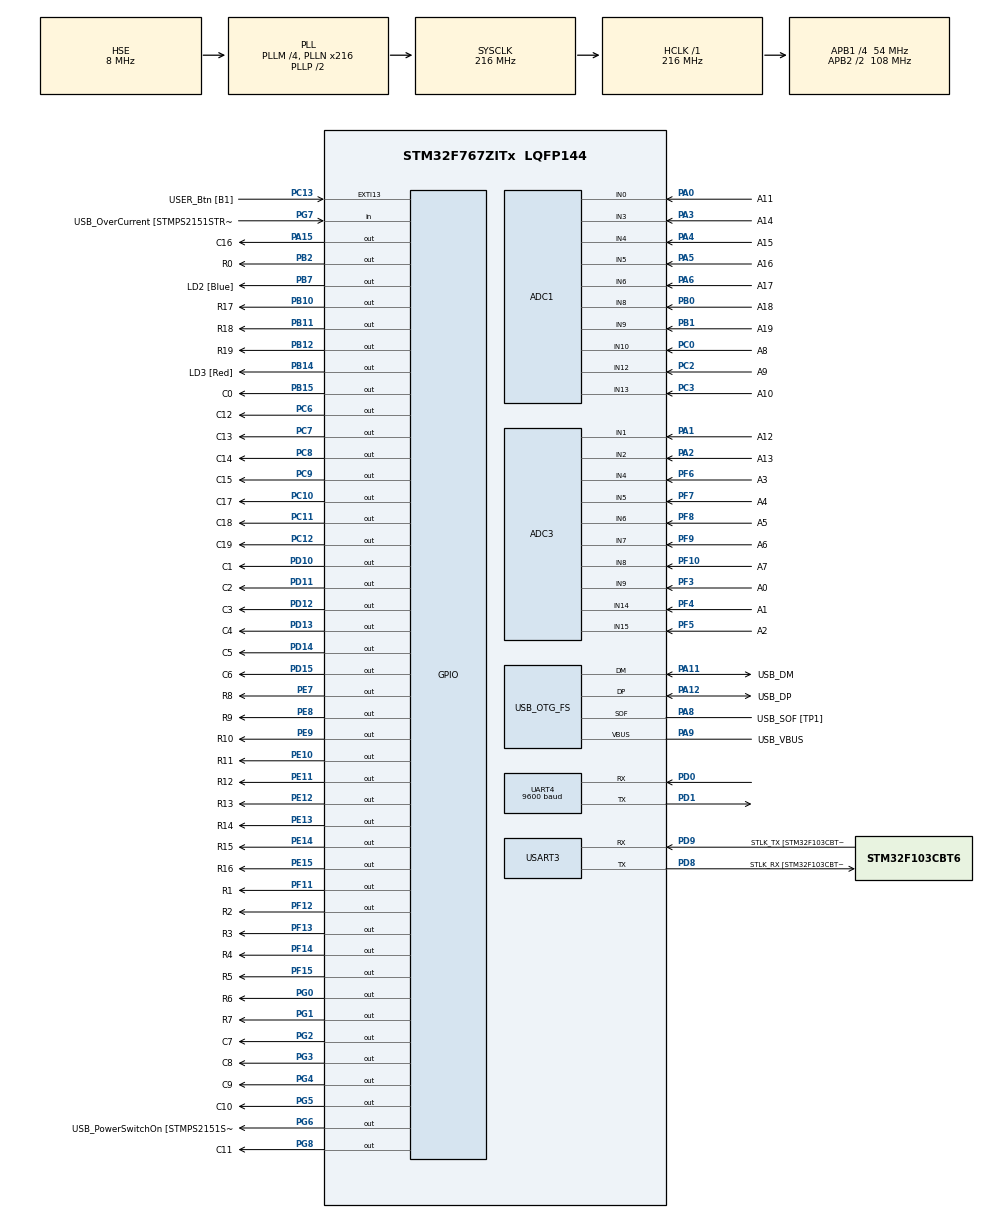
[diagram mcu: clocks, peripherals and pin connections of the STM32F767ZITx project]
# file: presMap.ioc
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ADC1.Channel-0\#ChannelRegularConversion=ADC_CHANNEL_0
ADC1.ContinuousConvMode=ENABLE
ADC1.EOCSelection=ADC_EOC_SEQ_CONV
ADC1.NbrOfConversion=1
ADC1.NbrOfConversionFlag=1
ADC1.Rank-0\#ChannelRegularConversion=1
ADC1.SamplingTime-0\#ChannelRegularConversion=ADC_SAMPLETIME_112CYCLES
ADC1.master=1
ADC3.Channel-3\#ChannelRegularConversion=ADC_CHANNEL_1
ADC3.ContinuousConvMode=ENABLE
ADC3.EOCSelection=ADC_EOC_SEQ_CONV
ADC3.NbrOfConversionFlag=1
ADC3.Rank-3\#ChannelRegularConversion=1
ADC3.SamplingTime-3\#ChannelRegularConversion=ADC_SAMPLETIME_112CYCLES
Dma.Request0=UART4_TX
Dma.UART4_TX.0.Direction=DMA_MEMORY_TO_PERIPH
Dma.UART4_TX.0.FIFOMode=DMA_FIFOMODE_DISABLE
Dma.UART4_TX.0.Instance=DMA1_Stream4
Dma.UART4_TX.0.MemDataAlignment=DMA_MDATAALIGN_BYTE
Dma.UART4_TX.0.MemInc=DMA_MINC_ENABLE
Dma.UART4_TX.0.Mode=DMA_CIRCULAR
Dma.UART4_TX.0.PeriphDataAlignment=DMA_PDATAALIGN_BYTE
Dma.UART4_TX.0.PeriphInc=DMA_PINC_DISABLE
Dma.UART4_TX.0.Priority=DMA_PRIORITY_MEDIUM
Mcu.Family=STM32F7
Mcu.Name=STM32F767ZITx
Mcu.Package=LQFP144
NVIC.DMA1_Stream4_IRQn=true\:0\:0\:false\:false\:true\:false
NVIC.OTG_FS_IRQn=true\:0\:0\:false\:false\:true\:false
NVIC.PriorityGroup=NVIC_PRIORITYGROUP_4
PA0/WKUP.GPIO_Label=A11
PA0/WKUP.Signal=ADCx_IN0
PA1.GPIO_Label=A12
PA1.Signal=ADCx_IN1
PA10.GPIO_Label=USB_ID
PA10.Signal=USB_OTG_FS_ID
PA11.GPIO_Label=USB_DM
PA11.Mode=Device_Only
PA11.Signal=USB_OTG_FS_DM
PA12.GPIO_Label=USB_DP
PA12.Mode=Device_Only
PA12.Signal=USB_OTG_FS_DP
PA13.GPIO_Label=TMS
PA13.Mode=Serial_Wire
PA13.Signal=SYS_JTMS-SWDIO
PA14.GPIO_Label=TCK
PA14.Mode=Serial_Wire
PA14.Signal=SYS_JTCK-SWCLK
PA15.GPIO_Label=C16
PA15.Signal=GPIO_Output
PA2.GPIO_Label=A13
PA2.Signal=ADCx_IN2
PA3.GPIO_Label=A14
PA3.Signal=ADCx_IN3
PA4.GPIO_Label=A15
PA4.Signal=ADCx_IN4
PA5.GPIO_Label=A16
PA5.Signal=ADCx_IN5
PA6.GPIO_Label=A17
PA6.Signal=ADCx_IN6
PA7.GPIO_Label=RMII_CRS_DV [LAN8742A-CZ-TR_CRS_DV]
PA7.Signal=ETH_CRS_DV
PA8.GPIO_Label=USB_SOF [TP1]
PA8.Mode=Activate_SOF_FS
PA8.Signal=USB_OTG_FS_SOF
PA9.GPIO_Label=USB_VBUS
PA9.Mode=Activate_VBUS
PA9.Signal=USB_OTG_FS_VBUS
PB0.GPIO_Label=A18
PB0.Signal=ADCx_IN8
PB1.GPIO_Label=A19
PB1.Signal=ADCx_IN9
PB10.GPIO_Label=R17
PB10.Signal=GPIO_Output
PB11.GPIO_Label=R18
PB11.Signal=GPIO_Output
PB12.GPIO_Label=R19
PB12.Signal=GPIO_Output
PB13.GPIO_Label=RMII_TXD1 [LAN8742A-CZ-TR_TXD1]
PB13.Signal=ETH_TXD1
PB14.GPIO_Label=LD3 [Red]
PB14.Signal=GPIO_Output
PB15.GPIO_Label=C0
PB15.Signal=GPIO_Output
PB2.GPIO_Label=R0
PB2.Signal=GPIO_Output
PB3.GPIO_Label=SWO
PB3.Signal=SYS_JTDO-SWO
PB7.GPIO_Label=LD2 [Blue]
PB7.Signal=GPIO_Output
PC0.GPIO_Label=A8
PC0.Signal=ADCx_IN10
PC1.GPIO_Label=RMII_MDC [LAN8742A-CZ-TR_MDC]
PC1.Signal=ETH_MDC
PC10.GPIO_Label=C17
PC10.Signal=GPIO_Output
PC11.GPIO_Label=C18
PC11.Signal=GPIO_Output
PC12.GPIO_Label=C19
PC12.Signal=GPIO_Output
PC13.GPIO_Label=USER_Btn [B1]
PC13.Signal=GPXTI13
PC14/OSC32_IN.Mode=LSE-External-Oscillator
PC14/OSC32_IN.Signal=RCC_OSC32_IN
PC15/OSC32_OUT.Mode=LSE-External-Oscillator
PC15/OSC32_OUT.Signal=RCC_OSC32_OUT
PC2.GPIO_Label=A9
PC2.Signal=ADCx_IN12
PC3.GPIO_Label=A10
PC3.Signal=ADCx_IN13
PC4.GPIO_Label=RMII_RXD0 [LAN8742A-CZ-TR_RXD0]
PC4.Signal=ETH_RXD0
PC5.GPIO_Label=RMII_RXD1 [LAN8742A-CZ-TR_RXD1]
PC5.Signal=ETH_RXD1
PC6.GPIO_Label=C12
PC6.Signal=GPIO_Output
PC7.GPIO_Label=C13
PC7.Signal=GPIO_Output
PC8.GPIO_Label=C14
PC8.Signal=GPIO_Output
PC9.GPIO_Label=C15
PC9.Signal=GPIO_Output
PD0.Mode=Asynchronous
PD0.Signal=UART4_RX
PD1.Mode=Asynchronous
PD1.Signal=UART4_TX
PD10.GPIO_Label=C1
PD10.Signal=GPIO_Output
PD11.GPIO_Label=C2
PD11.Signal=GPIO_Output
PD12.GPIO_Label=C3
PD12.Signal=GPIO_Output
PD13.GPIO_Label=C4
PD13.Signal=GPIO_Output
PD14.GPIO_Label=C5
PD14.Signal=GPIO_Output
PD15.GPIO_Label=C6
PD15.Signal=GPIO_Output
PD8.GPIO_Label=STLK_RX [STM32F103CBT6_PA3]
PD8.Mode=Asynchronous
PD8.Signal=USART3_TX
PD9.GPIO_Label=STLK_TX [STM32F103CBT6_PA2]
PD9.Mode=Asynchronous
PD9.Signal=USART3_RX
PE10.GPIO_Label=R11
PE10.Signal=GPIO_Output
PE11.GPIO_Label=R12
PE11.Signal=GPIO_Output
PE12.GPIO_Label=R13
PE12.Signal=GPIO_Output
PE13.GPIO_Label=R14
PE13.Signal=GPIO_Output
PE14.GPIO_Label=R15
PE14.Signal=GPIO_Output
PE15.GPIO_Label=R16
PE15.Signal=GPIO_Output
PE7.GPIO_Label=R8
PE7.Signal=GPIO_Output
PE8.GPIO_Label=R9
PE8.Signal=GPIO_Output
PE9.GPIO_Label=R10
PE9.Signal=GPIO_Output
PF10.GPIO_Label=A7
PF10.Mode=IN8
PF10.Signal=ADC3_IN8
PF11.GPIO_Label=R1
PF11.Signal=GPIO_Output
PF12.GPIO_Label=R2
PF12.Signal=GPIO_Output
PF13.GPIO_Label=R3
PF13.Signal=GPIO_Output
PF14.GPIO_Label=R4
PF14.Signal=GPIO_Output
PF15.GPIO_Label=R5
PF15.Signal=GPIO_Output
PF3.GPIO_Label=A0
PF3.Mode=IN9
PF3.Signal=ADC3_IN9
PF4.GPIO_Label=A1
PF4.Mode=IN14
PF4.Signal=ADC3_IN14
PF5.GPIO_Label=A2
PF5.Mode=IN15
PF5.Signal=ADC3_IN15
PF6.GPIO_Label=A3
PF6.Mode=IN4
PF6.Signal=ADC3_IN4
PF7.GPIO_Label=A4
PF7.Mode=IN5
PF7.Signal=ADC3_IN5
PF8.GPIO_Label=A5
PF8.Mode=IN6
PF8.Signal=ADC3_IN6
PF9.GPIO_Label=A6
PF9.Mode=IN7
PF9.Signal=ADC3_IN7
PG0.GPIO_Label=R6
PG0.Signal=GPIO_Output
PG1.GPIO_Label=R7
PG1.Signal=GPIO_Output
PG11.GPIO_Label=RMII_TX_EN [LAN8742A-CZ-TR_TXEN]
PG11.Signal=ETH_TX_EN
PG13.GPIO_Label=RMII_TXD0 [LAN8742A-CZ-TR_TXD0]
PG13.Signal=ETH_TXD0
PG2.GPIO_Label=C7
PG2.Signal=GPIO_Output
PG3.GPIO_Label=C8
PG3.Signal=GPIO_Output
PG4.GPIO_Label=C9
PG4.Signal=GPIO_Output
PG5.GPIO_Label=C10
PG5.Signal=GPIO_Output
PG6.GPIO_Label=USB_PowerSwitchOn [STMPS2151STR_EN]
PG6.Signal=GPIO_Output
PG7.GPIO_Label=USB_OverCurrent [STMPS2151STR_FAULT]
PG7.Signal=GPIO_Input
PG8.GPIO_Label=C11
PG8.Signal=GPIO_Output
PH0/OSC_IN.GPIO_Label=MCO [STM32F103CBT6_PA8]
PH0/OSC_IN.Mode=HSE-External-Clock-Source
PH0/OSC_IN.Signal=RCC_OSC_IN
PH1/OSC_OUT.Mode=HSE-External-Clock-Source
PH1/OSC_OUT.Signal=RCC_OSC_OUT
ProjectManager.HeapSize=0x200
ProjectManager.StackSize=0x400
ProjectManager.TargetToolchain=Makefile
RCC.48MHZClocksFreq_Value=24000000
RCC.AHBFreq_Value=216000000
RCC.APB1CLKDivider=RCC_HCLK_DIV4
RCC.APB1Freq_Value=54000000
RCC.APB1TimFreq_Value=108000000
RCC.APB2CLKDivider=RCC_HCLK_DIV2
RCC.APB2Freq_Value=108000000
RCC.APB2TimFreq_Value=216000000
RCC.CortexFreq_Value=216000000
RCC.HCLKFreq_Value=216000000
RCC.HSE_VALUE=8000000
RCC.HSI_VALUE=16000000
RCC.PLLM=4
RCC.PLLMUL=RCC_PLL_MUL9
RCC.PLLN=216
RCC.PLLQ=9
RCC.PRESCALERUSB=RCC_USBCLKSOURCE_PLL_DIV1_5
RCC.SYSCLKFreq_VALUE=216000000
RCC.SYSCLKSource=RCC_SYSCLKSOURCE_PLLCLK
RCC.SYSCLKSourceVirtual=RCC_SYSCLKSOURCE_PLLCLK
RCC.USBFreq_Value=48000000
RCC.VCOOutputFreq_Value=432000000
SH.ADCx_IN0.0=ADC1_IN0,IN0
SH.ADCx_IN1.0=ADC3_IN1,IN1
SH.ADCx_IN10.0=ADC1_IN10,IN10
SH.ADCx_IN12.0=ADC1_IN12,IN12
SH.ADCx_IN13.0=ADC1_IN13,IN13
SH.ADCx_IN2.0=ADC3_IN2,IN2
SH.ADCx_IN3.0=ADC1_IN3,IN3
SH.ADCx_IN4.0=ADC1_IN4,IN4
SH.ADCx_IN5.0=ADC1_IN5,IN5
SH.ADCx_IN6.0=ADC1_IN6,IN6
SH.ADCx_IN8.0=ADC1_IN8,IN8
SH.ADCx_IN9.0=ADC1_IN9,IN9
UART4.BaudRate=9600
USART3.VirtualMode-Asynchronous=VM_ASYNC
USB_DEVICE.CLASS_NAME_FS=CDC
USB_DEVICE.VirtualMode-CDC_FS=Cdc
USB_DEVICE.VirtualModeFS=Cdc_FS
USB_OTG_FS.VirtualMode=Device_Only
VP_USB_DEVICE_VS_USB_DEVICE_CDC_FS.Mode=CDC_FS
board=NUCLEO-F767ZI

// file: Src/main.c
/* USER CODE BEGIN Header */
/**
  ******************************************************************************
  * @file           : main.c
  * @brief          : Main program body
  ******************************************************************************
  ** This notice applies to any and all portions of this file
  * that are not between comment pairs USER CODE BEGIN and
  * USER CODE END. Other portions of this file, whether
  * inserted by the user or by software development tools
  * are owned by their respective copyright owners.
  *
  * COPYRIGHT(c) 2019 STMicroelectronics
  *
  * Redistribution and use in source and binary forms, with or without modification,
  * are permitted provided that the following conditions are met:
  *   1. Redistributions of source code must retain the above copyright notice,
  *      this list of conditions and the following disclaimer.
  *   2. Redistributions in binary form must reproduce the above copyright notice,
  *      this list of conditions and the following disclaimer in the documentation
  *      and/or other materials provided with the distribution.
  *   3. Neither the name of STMicroelectronics nor the names of its contributors
  *      may be used to endorse or promote products derived from this software
  *      without specific prior written permission.
  *
  * THIS SOFTWARE IS PROVIDED BY THE COPYRIGHT HOLDERS AND CONTRIBUTORS "AS IS"
  * AND ANY EXPRESS OR IMPLIED WARRANTIES, INCLUDING, BUT NOT LIMITED TO, THE
  * IMPLIED WARRANTIES OF MERCHANTABILITY AND FITNESS FOR A PARTICULAR PURPOSE ARE
  * DISCLAIMED. IN NO EVENT SHALL THE COPYRIGHT HOLDER OR CONTRIBUTORS BE LIABLE
  * FOR ANY DIRECT, INDIRECT, INCIDENTAL, SPECIAL, EXEMPLARY, OR CONSEQUENTIAL
  * DAMAGES (INCLUDING, BUT NOT LIMITED TO, PROCUREMENT OF SUBSTITUTE GOODS OR
  * SERVICES; LOSS OF USE, DATA, OR PROFITS; OR BUSINESS INTERRUPTION) HOWEVER
  * CAUSED AND ON ANY THEORY OF LIABILITY, WHETHER IN CONTRACT, STRICT LIABILITY,
  * OR TORT (INCLUDING NEGLIGENCE OR OTHERWISE) ARISING IN ANY WAY OUT OF THE USE
  * OF THIS SOFTWARE, EVEN IF ADVISED OF THE POSSIBILITY OF SUCH DAMAGE.
  *
  ******************************************************************************
  */
/* USER CODE END Header */

#include "main.h"
#include "adc.h"
#include "dma.h"
#include "usart.h"
#include "usb_device.h"
#include "gpio.h"

/* USER CODE BEGIN Includes */
#include "senMatrix.h"
#include "usbd_cdc_if.h"
/* USER CODE END Includes */

void SystemClock_Config(void);

int main(void)
{

  /* MCU Configuration--------------------------------------------------------*/

  /* Reset of all peripherals, Initializes the Flash interface and the Systick. */
  HAL_Init();

  /* Configure the system clock */
  SystemClock_Config();

  /* Initialize all configured peripherals */
  MX_GPIO_Init();
  MX_DMA_Init();
  MX_USART3_UART_Init();
  MX_ADC1_Init();
  MX_ADC3_Init();
  MX_USB_DEVICE_Init();
  MX_UART4_Init();
  /* USER CODE BEGIN 2 */
  matInit();
  /* USER CODE END 2 */

  /* Infinite loop */
  while (1)
  {

    /* USER CODE BEGIN 3 */

    //some delay so as not to kill the computer with high data rate
    //HAL_Delay(100);
    sampleAndSendAvgData();
  }

  /* USER CODE END 3 */
}

void SystemClock_Config(void)
{
  RCC_OscInitTypeDef RCC_OscInitStruct = {0};
  RCC_ClkInitTypeDef RCC_ClkInitStruct = {0};
  RCC_PeriphCLKInitTypeDef PeriphClkInitStruct = {0};

  /**Configure LSE Drive Capability
  */
  HAL_PWR_EnableBkUpAccess();
  /**Configure the main internal regulator output voltage
  */
  __HAL_RCC_PWR_CLK_ENABLE();
  __HAL_PWR_VOLTAGESCALING_CONFIG(PWR_REGULATOR_VOLTAGE_SCALE1);
  /**Initializes the CPU, AHB and APB busses clocks
  */
  RCC_OscInitStruct.OscillatorType = RCC_OSCILLATORTYPE_HSE;
  RCC_OscInitStruct.HSEState = RCC_HSE_BYPASS;
  RCC_OscInitStruct.PLL.PLLState = RCC_PLL_ON;
  RCC_OscInitStruct.PLL.PLLSource = RCC_PLLSOURCE_HSE;
  RCC_OscInitStruct.PLL.PLLM = 4;
  RCC_OscInitStruct.PLL.PLLN = 216;
  RCC_OscInitStruct.PLL.PLLP = RCC_PLLP_DIV2;
  RCC_OscInitStruct.PLL.PLLQ = 9;
  if (HAL_RCC_OscConfig(&RCC_OscInitStruct) != HAL_OK)
  {
    Error_Handler();
  }
  /**Activate the Over-Drive mode
  */
  if (HAL_PWREx_EnableOverDrive() != HAL_OK)
  {
    Error_Handler();
  }
  /**Initializes the CPU, AHB and APB busses clocks
  */
  RCC_ClkInitStruct.ClockType = RCC_CLOCKTYPE_HCLK|RCC_CLOCKTYPE_SYSCLK
                              |RCC_CLOCKTYPE_PCLK1|RCC_CLOCKTYPE_PCLK2;
  RCC_ClkInitStruct.SYSCLKSource = RCC_SYSCLKSOURCE_PLLCLK;
  RCC_ClkInitStruct.AHBCLKDivider = RCC_SYSCLK_DIV1;
  RCC_ClkInitStruct.APB1CLKDivider = RCC_HCLK_DIV4;
  RCC_ClkInitStruct.APB2CLKDivider = RCC_HCLK_DIV2;

  if (HAL_RCC_ClockConfig(&RCC_ClkInitStruct, FLASH_LATENCY_7) != HAL_OK)
  {
    Error_Handler();
  }
  PeriphClkInitStruct.PeriphClockSelection = RCC_PERIPHCLK_USART3|RCC_PERIPHCLK_UART4
                              |RCC_PERIPHCLK_CLK48;
  PeriphClkInitStruct.Usart3ClockSelection = RCC_USART3CLKSOURCE_PCLK1;
  PeriphClkInitStruct.Uart4ClockSelection = RCC_UART4CLKSOURCE_PCLK1;
  PeriphClkInitStruct.Clk48ClockSelection = RCC_CLK48SOURCE_PLL;
  if (HAL_RCCEx_PeriphCLKConfig(&PeriphClkInitStruct) != HAL_OK)
  {
    Error_Handler();
  }
}

void Error_Handler(void)
{
}

/************************ (C) COPYRIGHT STMicroelectronics *****END OF FILE****/
